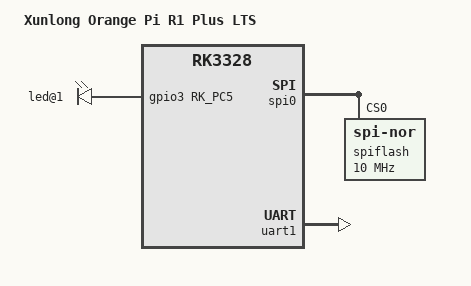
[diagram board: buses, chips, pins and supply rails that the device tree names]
// SPDX-License-Identifier: (GPL-2.0+ OR MIT)
/*
 * Copyright (c) 2020 Shenzhen Xunlong Software CO.,Limited
 * Copyright (c) 2021 AmadeusGhost <amadeus@jmu.edu.cn>
 *
 * Based on Nanopi R2S
 */

#include "rk3328-nanopi-r2-rev00.dts"

/ {
	model = "Xunlong Orange Pi R1 Plus LTS";
	compatible = "xunlong,orangepi-r1-plus", "rockchip,rk3328";
};

&leds_gpio {
	rockchip,pins =
		<2 RK_PB7 RK_FUNC_GPIO &pcfg_pull_none>,
		<2 RK_PC2 RK_FUNC_GPIO &pcfg_pull_none>,
		<3 RK_PC5 RK_FUNC_GPIO &pcfg_pull_none>;
};

&leds {
	led@1 {
		gpios = <&gpio3 RK_PC5 GPIO_ACTIVE_HIGH>;
	};
};

&mach {
	compatible = "orangepi,board";
	hwrev = <2>;
	machine = "ORANGEPI-R1PLUS";
	model = "OrangePi R1PLUS";
};

&spi0 {
	status = "okay";

	spiflash@0 {
		compatible = "jedec,spi-nor";
		reg = <0>;
		spi-max-frequency = <10000000>;
	};
};

&uart1 {
	status = "okay";
};
